AUTOSAR XML (schema 00046)
package /Cluster
  can cluster Powertrain: baudrate=500000, protocol-version=can2.0b, can-fd-baudrate=2000000
    can physical channel PowertrainChannel
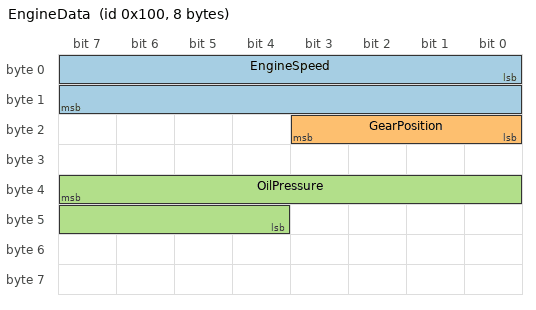
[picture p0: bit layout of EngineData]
      frame EngineData: id 0x100, frame-length=8, can-addressing-mode=STANDARD  # Engine status
        pdu EnginePdu: length=8, contained-i-pdu-props=header-id-short-header=0x010203
          signal EngineSpeed: start 0, 16 bit, little-endian, base-type=U16, compu {phys=raw*0.25 for raw 0..65535}, unit=rpm
          signal GearPosition: start 16, 4 bit, little-endian, base-type=U8, compu {0=Neutral, 1=First, 2=Second}
          signal OilPressure: start 39, 12 bit, big-endian, base-type=U16, compu {phys=raw*0.5-100 for raw 0..4095}, unit=kPa
      frame Bundle: id 0x200, frame-length=64, can-addressing-mode=STANDARD, can-frame-rx-behavior=CAN-FD, can-frame-tx-behavior=CAN-FD
        container i pdu Bundle: length=64, contained-pdu-triggering=[EnginePdu_triggering, StatusPdu_triggering], header-type=SHORT-HEADER
      pdu triggering StatusPdu_triggering: pdu=StatusPdu
  can cluster Chassis: baudrate=250000, protocol-version=can2.0b
    can physical channel ChassisChannel
      frame WheelSpeeds: id 0x100, frame-length=8, can-addressing-mode=STANDARD
        pdu WheelPdu: length=8
          signal WheelSpeedFrontLeft: start 0, 16 bit, little-endian, base-type=U16, compu {phys=raw*0.01 for raw 0..65535}, unit=km/h
package /ISignalIPdu
  pdu StatusPdu: length=2, contained-i-pdu-props=header-id-short-header=0x0A0B0C
    signal AliveCounter: start 0, 8 bit, little-endian, base-type=U8, compu {identical}
package /Unit
  unit rpm: display-name=rpm
  unit kPa: display-name=kPa
  unit kmh: display-name=km/h
package /SwBaseType
  base type U8: category=FIXED_LENGTH, base-type-size=8, base-type-encoding=NONE
  base type U16: category=FIXED_LENGTH, base-type-size=16, base-type-encoding=NONE
package /System
  system TestSystem: category=SYSTEM_EXTRACT, container-i-pdu-header-byte-order=big-endian
